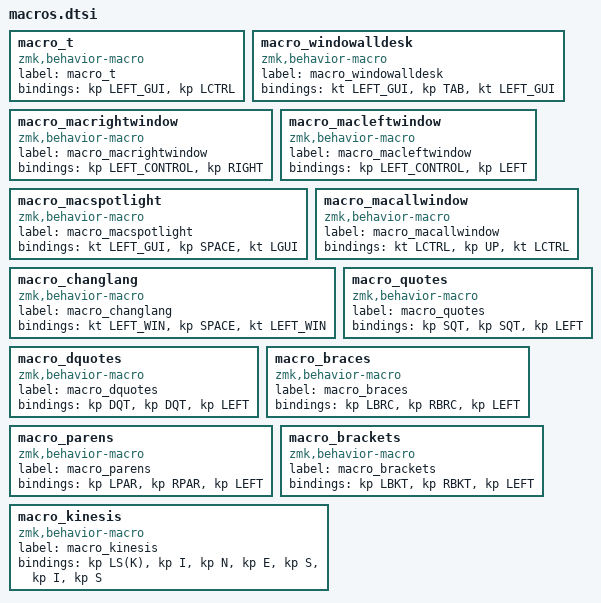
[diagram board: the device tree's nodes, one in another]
macro_t: macro_t{
compatible = "zmk,behavior-macro";
label = "macro_t";
#binding-cells = <0>;
bindings = <&kp LEFT_GUI>, <&kp LCTRL>;
};
macro_windowalldesk: macro_windowalldesk{
compatible = "zmk,behavior-macro";
label = "macro_windowalldesk";
#binding-cells = <0>;
bindings = <&kt LEFT_GUI>, <&kp TAB>, <&kt LEFT_GUI>;
};
macro_macrightwindow: macro_macrightwindow{
compatible = "zmk,behavior-macro";
label = "macro_macrightwindow";
#binding-cells = <0>;
bindings = <&kp LEFT_CONTROL>, <&kp RIGHT>;
};
macro_macleftwindow: macro_macleftwindow{
compatible = "zmk,behavior-macro";
label = "macro_macleftwindow";
#binding-cells = <0>;
bindings = <&kp LEFT_CONTROL>, <&kp LEFT>;
};
macro_macspotlight: macro_macspotlight{
compatible = "zmk,behavior-macro";
label = "macro_macspotlight";
#binding-cells = <0>;
bindings = <&kt LEFT_GUI>, <&kp SPACE>, <&kt LGUI>;
};
macro_macallwindow: macro_macallwindow{
compatible = "zmk,behavior-macro";
label = "macro_macallwindow";
#binding-cells = <0>;
bindings = <&kt LCTRL>, <&kp UP>, <&kt LCTRL>;
};
macro_changlang: macro_changlang{
compatible = "zmk,behavior-macro";
label = "macro_changlang";
#binding-cells = <0>;
bindings = <&kt LEFT_WIN>, <&kp SPACE>, <&kt LEFT_WIN>;
};
macro_quotes: macro_quotes{
compatible = "zmk,behavior-macro";
label = "macro_quotes";
#binding-cells = <0>;
bindings = <&kp SQT>, <&kp SQT>, <&kp LEFT>;
};
macro_dquotes: macro_dquotes{
compatible = "zmk,behavior-macro";
label = "macro_dquotes";
#binding-cells = <0>;
bindings = <&kp DQT>, <&kp DQT>, <&kp LEFT>;
};
macro_braces: macro_braces{
compatible = "zmk,behavior-macro";
label = "macro_braces";
#binding-cells = <0>;
bindings = <&kp LBRC>, <&kp RBRC>, <&kp LEFT>;
};
macro_parens: macro_parens{
compatible = "zmk,behavior-macro";
label = "macro_parens";
#binding-cells = <0>;
bindings = <&kp LPAR>, <&kp RPAR>, <&kp LEFT>;
};
macro_brackets: macro_brackets{
compatible = "zmk,behavior-macro";
label = "macro_brackets";
#binding-cells = <0>;
bindings = <&kp LBKT>, <&kp RBKT>, <&kp LEFT>;
};
macro_kinesis: macro_kinesis{
compatible = "zmk,behavior-macro";
label = "macro_kinesis";
#binding-cells = <0>;
bindings = <&kp LS(K)>, <&kp I>, <&kp N>, <&kp E>, <&kp S>, <&kp I>, <&kp S>;
};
